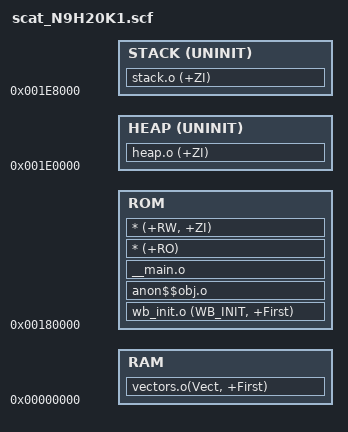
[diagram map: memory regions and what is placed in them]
;/**************************************************************************//**
; * @file     scat_N9H20K1.scf
; * @brief    N9H20K1 series scatter code
; *
; * SPDX-License-Identifier: Apache-2.0
; * @copyright (C) 2020 Nuvoton Technology Corp. All rights reserved.
; *****************************************************************************/

ROM_LOAD 0x180000
{
    ROM +0
    {
        wb_init.o (WB_INIT, +First)
        anon$$obj.o
        __main.o
        * (+RO)
        * (+RW, +ZI) 
        
    }
    
    RAM 0x0
    {
        vectors.o(Vect, +First)  
    }
      
    
    HEAP 0x1E0000 UNINIT
    {
        heap.o (+ZI)
    }

    STACK 0x1E8000 UNINIT
    {
        stack.o (+ZI)
    }
}
